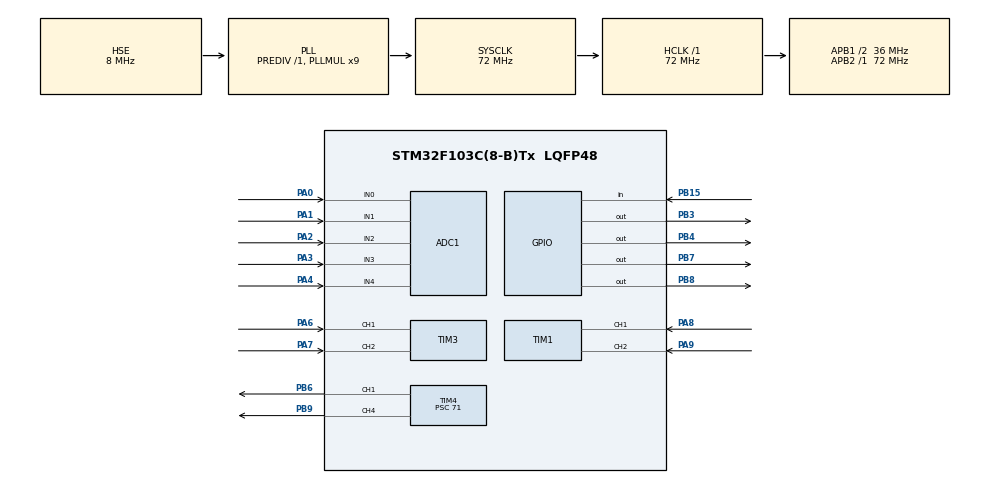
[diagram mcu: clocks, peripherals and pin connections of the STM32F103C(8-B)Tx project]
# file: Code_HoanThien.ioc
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ADC1.Channel-0\#ChannelRegularConversion=ADC_CHANNEL_0
ADC1.Channel-1\#ChannelRegularConversion=ADC_CHANNEL_1
ADC1.Channel-2\#ChannelRegularConversion=ADC_CHANNEL_2
ADC1.Channel-3\#ChannelRegularConversion=ADC_CHANNEL_3
ADC1.Channel-4\#ChannelRegularConversion=ADC_CHANNEL_4
ADC1.ContinuousConvMode=ENABLE
ADC1.NbrOfConversion=5
ADC1.NbrOfConversionFlag=1
ADC1.Rank-0\#ChannelRegularConversion=1
ADC1.Rank-1\#ChannelRegularConversion=2
ADC1.Rank-2\#ChannelRegularConversion=3
ADC1.Rank-3\#ChannelRegularConversion=4
ADC1.Rank-4\#ChannelRegularConversion=5
ADC1.SamplingTime-0\#ChannelRegularConversion=ADC_SAMPLETIME_239CYCLES_5
ADC1.SamplingTime-1\#ChannelRegularConversion=ADC_SAMPLETIME_239CYCLES_5
ADC1.SamplingTime-2\#ChannelRegularConversion=ADC_SAMPLETIME_239CYCLES_5
ADC1.SamplingTime-3\#ChannelRegularConversion=ADC_SAMPLETIME_239CYCLES_5
ADC1.SamplingTime-4\#ChannelRegularConversion=ADC_SAMPLETIME_239CYCLES_5
ADC1.master=1
Dma.ADC1.0.Direction=DMA_PERIPH_TO_MEMORY
Dma.ADC1.0.Instance=DMA1_Channel1
Dma.ADC1.0.MemDataAlignment=DMA_MDATAALIGN_HALFWORD
Dma.ADC1.0.MemInc=DMA_MINC_ENABLE
Dma.ADC1.0.Mode=DMA_CIRCULAR
Dma.ADC1.0.PeriphDataAlignment=DMA_PDATAALIGN_HALFWORD
Dma.ADC1.0.PeriphInc=DMA_PINC_DISABLE
Dma.ADC1.0.Priority=DMA_PRIORITY_LOW
Dma.Request0=ADC1
Mcu.Family=STM32F1
Mcu.Name=STM32F103C(8-B)Tx
Mcu.Package=LQFP48
NVIC.DMA1_Channel1_IRQn=true\:0\:0\:false\:false\:false\:false\:true\:true
NVIC.PriorityGroup=NVIC_PRIORITYGROUP_4
NVIC.TIM2_IRQn=true\:1\:0\:true\:false\:true\:true\:true\:true
PA0-WKUP.Signal=ADCx_IN0
PA1.Signal=ADCx_IN1
PA13.Mode=Serial_Wire
PA13.Signal=SYS_JTMS-SWDIO
PA14.Mode=Serial_Wire
PA14.Signal=SYS_JTCK-SWCLK
PA2.Signal=ADCx_IN2
PA3.Signal=ADCx_IN3
PA4.Signal=ADCx_IN4
PA6.Signal=S_TIM3_CH1
PA7.Signal=S_TIM3_CH2
PA8.Signal=S_TIM1_CH1
PA9.Signal=S_TIM1_CH2
PB15.GPIO_PuPd=GPIO_PULLUP
PB15.Signal=GPIO_Input
PB3.Signal=GPIO_Output
PB4.Signal=GPIO_Output
PB6.Signal=S_TIM4_CH1
PB7.Signal=GPIO_Output
PB8.Signal=GPIO_Output
PB9.Signal=S_TIM4_CH4
PD0-OSC_IN.Mode=HSE-External-Oscillator
PD0-OSC_IN.Signal=RCC_OSC_IN
PD1-OSC_OUT.Mode=HSE-External-Oscillator
PD1-OSC_OUT.Signal=RCC_OSC_OUT
ProjectManager.HeapSize=0x200
ProjectManager.StackSize=0x400
ProjectManager.TargetToolchain=STM32CubeIDE
RCC.ADCPresc=RCC_ADCPCLK2_DIV6
RCC.AHBFreq_Value=72000000
RCC.APB1CLKDivider=RCC_HCLK_DIV2
RCC.APB1Freq_Value=36000000
RCC.APB1TimFreq_Value=72000000
RCC.APB2Freq_Value=72000000
RCC.APB2TimFreq_Value=72000000
RCC.HCLKFreq_Value=72000000
RCC.PLLMUL=RCC_PLL_MUL9
RCC.PLLSourceVirtual=RCC_PLLSOURCE_HSE
RCC.SYSCLKFreq_VALUE=72000000
RCC.SYSCLKSource=RCC_SYSCLKSOURCE_PLLCLK
RCC.USBFreq_Value=72000000
SH.ADCx_IN0.0=ADC1_IN0,IN0
SH.ADCx_IN1.0=ADC1_IN1,IN1
SH.ADCx_IN2.0=ADC1_IN2,IN2
SH.ADCx_IN3.0=ADC1_IN3,IN3
SH.ADCx_IN4.0=ADC1_IN4,IN4
SH.S_TIM1_CH1.0=TIM1_CH1,Encoder_Interface
SH.S_TIM1_CH2.0=TIM1_CH2,Encoder_Interface
SH.S_TIM3_CH1.0=TIM3_CH1,Encoder_Interface
SH.S_TIM3_CH2.0=TIM3_CH2,Encoder_Interface
SH.S_TIM4_CH1.0=TIM4_CH1,PWM Generation1 CH1
SH.S_TIM4_CH4.0=TIM4_CH4,PWM Generation4 CH4
TIM1.EncoderMode=TIM_ENCODERMODE_TI12
TIM1.IC1Filter=6
TIM1.IC2Filter=6
TIM2.AutoReloadPreload=TIM_AUTORELOAD_PRELOAD_ENABLE
TIM2.Period=9999
TIM2.Prescaler=71
TIM3.EncoderMode=TIM_ENCODERMODE_TI12
TIM3.IC1Filter=6
TIM3.IC2Filter=6
TIM4.AutoReloadPreload=TIM_AUTORELOAD_PRELOAD_ENABLE
TIM4.Channel-PWM\ Generation1\ CH1=TIM_CHANNEL_1
TIM4.Channel-PWM\ Generation4\ CH4=TIM_CHANNEL_4
TIM4.Period=999
TIM4.Prescaler=71
VP_TIM2_VS_ClockSourceINT.Mode=Internal
VP_TIM4_VS_ClockSourceINT.Mode=Internal
board=custom

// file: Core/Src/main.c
/* USER CODE BEGIN Header */
/**
  ******************************************************************************
  * @file           : main.c
  * @brief          : Main program body
  ******************************************************************************
  * @attention
  *
  * Copyright (c) 2026 STMicroelectronics.
  * All rights reserved.
  *
  * This software is licensed under terms that can be found in the LICENSE file
  * in the root directory of this software component.
  * If no LICENSE file comes with this software, it is provided AS-IS.
  *
  ******************************************************************************
  */
/* USER CODE END Header */
#include <robot_config.h>
#include "main.h"
#include "adc.h"
#include "dma.h"
#include "tim.h"
#include "gpio.h"
#include "robot_app.h"
#include "drive.h"
#include "control.h"
#include "line_sensor.h"

void SystemClock_Config(void);

int main(void)
{

  /* MCU Configuration--------------------------------------------------------*/

  /* Reset of all peripherals, Initializes the Flash interface and the Systick. */
  HAL_Init();

  /* Configure the system clock */
  SystemClock_Config();

  /* Initialize all configured peripherals */
  MX_GPIO_Init();
  MX_DMA_Init();
  MX_ADC1_Init();
  MX_TIM1_Init();
  MX_TIM3_Init();
  MX_TIM4_Init();
  MX_TIM2_Init();
  /* USER CODE BEGIN 2 */
  RobotApp_Init(&hadc1, &htim3, &htim1, &htim4);
  HAL_TIM_Base_Start_IT(&htim2);
  /* USER CODE END 2 */

  /* Infinite loop */
  while (1)
  {

  }
}

void SystemClock_Config(void)
{
  RCC_OscInitTypeDef RCC_OscInitStruct = {0};
  RCC_ClkInitTypeDef RCC_ClkInitStruct = {0};
  RCC_PeriphCLKInitTypeDef PeriphClkInit = {0};

  /** Initializes the RCC Oscillators according to the specified parameters
  * in the RCC_OscInitTypeDef structure.
  */
  RCC_OscInitStruct.OscillatorType = RCC_OSCILLATORTYPE_HSE;
  RCC_OscInitStruct.HSEState = RCC_HSE_ON;
  RCC_OscInitStruct.HSEPredivValue = RCC_HSE_PREDIV_DIV1;
  RCC_OscInitStruct.HSIState = RCC_HSI_ON;
  RCC_OscInitStruct.PLL.PLLState = RCC_PLL_ON;
  RCC_OscInitStruct.PLL.PLLSource = RCC_PLLSOURCE_HSE;
  RCC_OscInitStruct.PLL.PLLMUL = RCC_PLL_MUL9;
  if (HAL_RCC_OscConfig(&RCC_OscInitStruct) != HAL_OK)
  {
    Error_Handler();
  }

  /** Initializes the CPU, AHB and APB buses clocks
  */
  RCC_ClkInitStruct.ClockType = RCC_CLOCKTYPE_HCLK|RCC_CLOCKTYPE_SYSCLK
                              |RCC_CLOCKTYPE_PCLK1|RCC_CLOCKTYPE_PCLK2;
  RCC_ClkInitStruct.SYSCLKSource = RCC_SYSCLKSOURCE_PLLCLK;
  RCC_ClkInitStruct.AHBCLKDivider = RCC_SYSCLK_DIV1;
  RCC_ClkInitStruct.APB1CLKDivider = RCC_HCLK_DIV2;
  RCC_ClkInitStruct.APB2CLKDivider = RCC_HCLK_DIV1;

  if (HAL_RCC_ClockConfig(&RCC_ClkInitStruct, FLASH_LATENCY_2) != HAL_OK)
  {
    Error_Handler();
  }
  PeriphClkInit.PeriphClockSelection = RCC_PERIPHCLK_ADC;
  PeriphClkInit.AdcClockSelection = RCC_ADCPCLK2_DIV6;
  if (HAL_RCCEx_PeriphCLKConfig(&PeriphClkInit) != HAL_OK)
  {
    Error_Handler();
  }
}

/* USER CODE BEGIN 4 */
void HAL_TIM_PeriodElapsedCallback(TIM_HandleTypeDef *htim) {
    // Ngắt TIM2 tự động xảy ra chính xác mỗi 10ms (0.01s)
    if (htim->Instance == TIM2) {
        RobotApp_Tick10ms_ISR();
    }
}
/* USER CODE END 4 */

void Error_Handler(void)
{
  __disable_irq();
  while (1)
  {
  }
}
